# CC1350F128 register map
File version: 1.0
CPU: CM3 1.0, other endian, MPU, FPU, 3 interrupt priority bits
Registers are 32-bit, read-write, reset 0x0 unless marked. A register's access mark holds for its fields unless they carry their own. Offsets are from the block's base; [hi:lo] are bit positions.

## AUX_WUC — AUX Wake-up controller
Base 0x400C6000
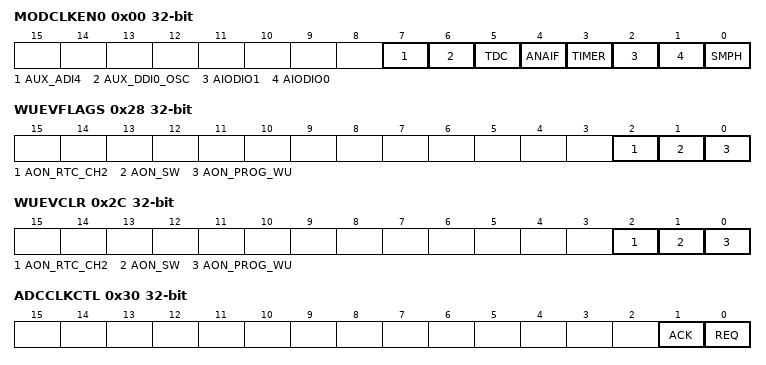
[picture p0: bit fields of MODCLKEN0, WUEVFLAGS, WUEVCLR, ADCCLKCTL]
0x00 MODCLKEN0 — Module Clock Enable Clock enable for each module in the AUX domain For use by the system CPU The settings in this register are OR'ed with the corresponding settings in MODCLKEN1. This allows the system CPU and AUX_SCE to request clocks independently. Settings take effect immediately.
  [7] AUX_ADI4 — [7:7] Enables (1) or disables (0) clock for AUX_ADI4.
    1=EN (System CPU has requested clock for AUX_ADI4); 0=DIS (System CPU has not requested clock for AUX_ADI4)
  [6] AUX_DDI0_OSC — [6:6] Enables (1) or disables (0) clock for AUX_DDI0_OSC.
    1=EN (System CPU has requested clock for AUX_DDI0_OSC); 0=DIS (System CPU has not requested clock for AUX_DDI0_OSC)
  [5] TDC — [5:5] Enables (1) or disables (0) clock for AUX_TDCIF. Note that the TDC counter and reference clock sources must be requested separately using TDCCLKCTL and REFCLKCTL, respectively.
    1=EN (System CPU has requested clock for TDC); 0=DIS (System CPU has not requested clock for TDC)
  [4] ANAIF — [4:4] Enables (1) or disables (0) clock for AUX_ANAIF. Note that the ADC internal clock must be requested separately using ADCCLKCTL.
    1=EN (System CPU has requested clock for ANAIF); 0=DIS (System CPU has not requested clock for ANAIF)
  [3] TIMER — [3:3] Enables (1) or disables (0) clock for AUX_TIMER.
    1=EN (System CPU has requested clock for TIMER); 0=DIS (System CPU has not requested clock for TIMER)
  [2] AIODIO1 — [2:2] Enables (1) or disables (0) clock for AUX_AIODIO1.
    1=EN (System CPU has requested clock for AIODIO1); 0=DIS (System CPU has not requested clock for AIODIO1)
  [1] AIODIO0 — [1:1] Enables (1) or disables (0) clock for AUX_AIODIO0.
    1=EN (System CPU has requested clock for AIODIO0); 0=DIS (System CPU has not requested clock for AIODIO0)
  [0] SMPH — [0:0] Enables (1) or disables (0) clock for AUX_SMPH.
    1=EN (System CPU has requested clock for SMPH); 0=DIS (System CPU has not requested clock for SMPH)
0x04 PWROFFREQ — Power Off Request Requests power off request for the AUX domain. When powered off, the power supply and clock is disabled. This may only be used when taking the entire device into shutdown mode (i.e. with full device reset when resuming operation). Power off is prevented if AON_WUC:AUXCTL.AUX_FORCE_ON has been set, or if MCUBUSCTL.DISCONNECT_REQ has been cleared.
  [0] REQ — [0:0] Power off request 0: No action 1: Request to power down AUX. Once set, this bit shall not be cleared. The bit will be reset again when AUX is powered up again. The request will only happen if AONCTLSTAT.AUX_FORCE_ON = 0 and MCUBUSSTAT.DISCONNECTED=1.
0x08 PWRDWNREQ — Power Down Request Request from AUX for system to enter power down. When system is in power down there is limited current supply available and the clock source is set by AON_WUC:AUXCLK.PWR_DWN_SRC
  [0] REQ — [0:0] Power down request 0: Request for system to be in active mode 1: Request for system to be in power down mode When REQ is 1 one shall assume that the system is in power down, and that current supply is limited. When setting REQ = 0, one shall assume that the system is in power down until PWRDWNACK.ACK = 0
0x0C PWRDWNACK — Power Down Acknowledgment
  [0] ACK ro — [0:0] Power down acknowledgment. Indicates whether the power down request given by PWRDWNREQ.REQ is captured by the AON domain or not 0: AUX can assume that the system is in active mode 1: The request for power down is acknowledged and the AUX must act like the system is in power down mode and power supply is limited The system CPU cannot use this bit since the bus bridge between MCU domain and AUX domain is always disconnected when this bit is set. For AUX_SCE use only
0x10 CLKLFREQ — Low Frequency Clock Request
  [0] REQ — [0:0] Low frequency request 0: Request clock frequency to be controlled by AON_WUC:AUXCLK and the system state 1: Request low frequency clock SCLK_LF as the clock source for AUX This bit must not be modified unless CLKLFACK.ACK matches the current value
0x14 CLKLFACK — Low Frequency Clock Acknowledgment
  [0] ACK ro — [0:0] Acknowledgment of CLKLFREQ.REQ 0: Acknowledgement that clock frequency is controlled by AON_WUC:AUXCLK and the system state 1: Acknowledgement that the low frequency clock SCLK_LF is the clock source for AUX
0x28 WUEVFLAGS — Wake-up Event Flags Status of wake-up events from the AON domain The event flags are cleared by setting the corresponding bits in WUEVCLR
  [2] AON_RTC_CH2 ro — [2:2] Indicates pending event from AON_RTC_CH2 compare. Note that this flag will be set whenever the AON_RTC_CH2 event happens, but that does not mean that this event is a wake-up event. To make the AON_RTC_CH2 a wake-up event for the AUX domain configure it as a wake-up event in AON_EVENT:AUXWUSEL.WU0_EV, AON_EVENT:AUXWUSEL.WU1_EV or AON_EVENT:AUXWUSEL.WU2_EV.
  [1] AON_SW ro — [1:1] Indicates pending event triggered by system CPU writing a 1 to AON_WUC:AUXCTL.SWEV.
  [0] AON_PROG_WU ro — [0:0] Indicates pending event triggered by the sources selected in AON_EVENT:AUXWUSEL.WU0_EV, AON_EVENT:AUXWUSEL.WU1_EV and AON_EVENT:AUXWUSEL.WU2_EV.
0x2C WUEVCLR — Wake-up Event Clear Clears wake-up events from the AON domain
  [2] AON_RTC_CH2 — [2:2] Set to clear the WUEVFLAGS.AON_RTC_CH2 wake-up event. Note that if RTC channel 2 is also set as source for AON_PROG_WU this field can also clear WUEVFLAGS.AON_PROG_WU This bit must remain set until WUEVFLAGS.AON_RTC_CH2 returns to 0.
  [1] AON_SW — [1:1] Set to clear the WUEVFLAGS.AON_SW wake-up event. This bit must remain set until WUEVFLAGS.AON_SW returns to 0.
  [0] AON_PROG_WU — [0:0] Set to clear the WUEVFLAGS.AON_PROG_WU wake-up event. Note only if an IO event is selected as wake-up event, is it possible to use this field to clear the source. Other sources cannot be cleared using this field. The IO pin needs to be assigned to AUX in the IOC and the input enable for the pin needs to be set in AIODIO0 or AIODIO1 for this clearing to take effect. This bit must remain set until WUEVFLAGS.AON_PROG_WU returns to 0.
0x30 ADCCLKCTL — ADC Clock Control Controls the ADC internal clock Note that the ADC command and data interface requires MODCLKEN0.ANAIF or MODCLKEN1.ANAIF also to be set
  [1] ACK ro — [1:1] Acknowledges the last value written to REQ.
  [0] REQ — [0:0] Enables(1) or disables (0) the ADC internal clock. This bit must not be modified unless ACK matches the current value.
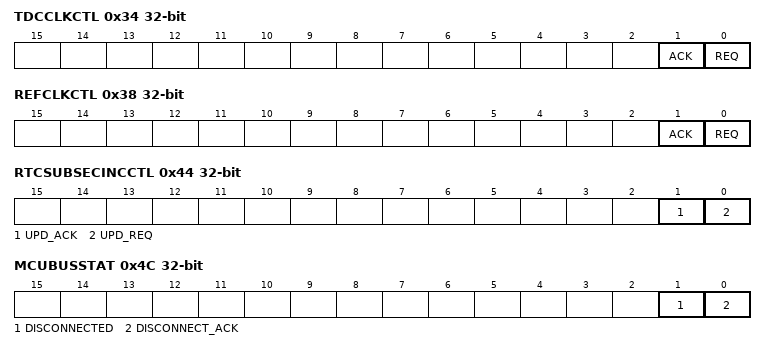
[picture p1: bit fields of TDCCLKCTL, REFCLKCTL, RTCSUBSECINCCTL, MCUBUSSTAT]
0x34 TDCCLKCTL — TDC Clock Control Controls the TDC counter clock source, which steps the TDC counter value The source of this clock is controlled by OSC_DIG:CTL0.ACLK_TDC_SRC_SEL.
  [1] ACK ro — [1:1] Acknowledges the last value written to REQ.
  [0] REQ — [0:0] Enables(1) or disables (0) the TDC counter clock source. This bit must not be modified unless ACK matches the current value.
0x38 REFCLKCTL — Reference Clock Control Controls the TDC reference clock source, which is to be compared against the TDC counter clock. The source of this clock is controlled by OSC_DIG:CTL0.ACLK_REF_SRC_SEL.
  [1] ACK ro — [1:1] Acknowledges the last value written to REQ.
  [0] REQ — [0:0] Enables(1) or disables (0) the TDC reference clock source. This bit must not be modified unless ACK matches the current value.
0x3C RTCSUBSECINC0 — Real Time Counter Sub Second Increment 0 New value for the real-time counter (AON_RTC) sub-second increment value, part corresponding to AON_RTC:SUBSECINC bits 15:0. After setting INC15_0 and RTCSUBSECINC1.INC23_16, the value is loaded into AON_RTC:SUBSECINC.VALUEINC by setting RTCSUBSECINCCTL.UPD_REQ.
  [15:0] INC15_0 — [15:0] Bits 15:0 of the RTC sub-second increment value.
0x40 RTCSUBSECINC1 — Real Time Counter Sub Second Increment 1 New value for the real-time counter (AON_RTC) sub-second increment value, part corresponding to AON_RTC:SUBSECINC bits 23:16. After setting RTCSUBSECINC0.INC15_0 and INC23_16, the value is loaded into AON_RTC:SUBSECINC.VALUEINC by setting RTCSUBSECINCCTL.UPD_REQ.
  [7:0] INC23_16 — [7:0] Bits 23:16 of the RTC sub-second increment value.
0x44 RTCSUBSECINCCTL — Real Time Counter Sub Second Increment Control
  [1] UPD_ACK ro — [1:1] Acknowledgment of the UPD_REQ.
  [0] UPD_REQ — [0:0] Signal that a new real time counter sub second increment value is available 0: New sub second increment is not available 1: New sub second increment is available This bit must not be modified unless UPD_ACK matches the current value.
0x48 MCUBUSCTL — MCU Bus Control Controls the connection between the AUX domain bus and the MCU domain bus. The buses must be disconnected to allow power-down or power-off of the AUX domain.
  [0] DISCONNECT_REQ — [0:0] Requests the AUX domain bus to be disconnected from the MCU domain bus. The request has no effect when AON_WUC:AUX_CTL.AUX_FORCE_ON is set. The disconnection status can be monitored through MCUBUSSTAT. Note however that this register cannot be read by the system CPU while disconnected. It is recommended that this bit is set and remains set after initial power-up, and that the system CPU uses AON_WUC:AUX_CTL.AUX_FORCE_ON to connect/disconnect the bus.
0x4C MCUBUSSTAT — MCU Bus Status Indicates the connection state of the AUX domain and MCU domain buses. Note that this register cannot be read from the MCU domain while disconnected, and is therefore only useful for the AUX_SCE.
  [1] DISCONNECTED ro — [1:1] Indicates whether the AUX domain and MCU domain buses are currently disconnected (1) or connected (0).
  [0] DISCONNECT_ACK ro — [0:0] Acknowledges reception of the bus disconnection request, by matching the value of MCUBUSCTL.DISCONNECT_REQ. Note that if AON_WUC:AUXCTL.AUX_FORCE_ON = 1 a reconnect to the MCU domain bus will be made regardless of the state of MCUBUSCTL.DISCONNECT_REQ
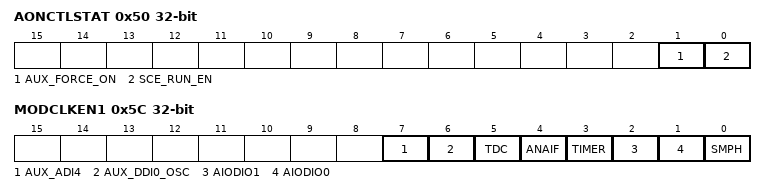
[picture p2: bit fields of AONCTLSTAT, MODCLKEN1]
0x50 AONCTLSTAT — AON Domain Control Status Status of AUX domain control from AON_WUC.
  [1] AUX_FORCE_ON ro — [1:1] Status of AON_WUC:AUX_CTL.AUX_FORCE_ON.
  [0] SCE_RUN_EN ro — [0:0] Status of AON_WUC:AUX_CTL.SCE_RUN_EN.
0x54 AUXIOLATCH — AUX Input Output Latch Controls latching of signals between AUX_AIODIO0/AUX_AIODIO1 and AON_IOC.
  [0] EN — [0:0] Opens (1) or closes (0) the AUX_AIODIO0/AUX_AIODIO1 signal latching. At startup, set EN = TRANSP before configuring AUX_AIODIO0/AUX_AIODIO1 and subsequently selecting AUX mode in the AON_IOC. When powering off the AUX domain (using PWROFFREQ.REQ), set EN = STATIC in advance preserve the current state (mode and output value) of the I/O pins.
    1=TRANSP (Latches are transparent ( open )); 0=STATIC (Latches are static ( closed ))
0x5C MODCLKEN1 — Module Clock Enable 1 Clock enable for each module in the AUX domain, for use by the AUX_SCE. Settings take effect immediately. The settings in this register are OR'ed with the corresponding settings in MODCLKEN0. This allows system CPU and AUX_SCE to request clocks independently.
  [7] AUX_ADI4 — [7:7] Enables (1) or disables (0) clock for AUX_ADI4.
    1=EN (AUX_SCE has requested clock for AUX_ADI4); 0=DIS (AUX_SCE has not requested clock for AUX_ADI4)
  [6] AUX_DDI0_OSC — [6:6] Enables (1) or disables (0) clock for AUX_DDI0_OSC.
    1=EN (AUX_SCE has requested clock for AUX_DDI0_OSC); 0=DIS (AUX_SCE has not requested clock for AUX_DDI0_OSC)
  [5] TDC — [5:5] Software should not rely on the value of a reserved. Writing any other value than the reset value may result in undefined behavior.
  [4] ANAIF — [4:4] Enables (1) or disables (0) clock for AUX_ANAIF.
    1=EN (AUX_SCE has requested clock for ANAIF); 0=DIS (AUX_SCE has not requested clock for ANAIF)
  [3] TIMER — [3:3] Enables (1) or disables (0) clock for AUX_TIMER.
    1=EN (AUX_SCE has requested clock for TIMER); 0=DIS (AUX_SCE has not requested clock for TIMER)
  [2] AIODIO1 — [2:2] Enables (1) or disables (0) clock for AUX_AIODIO1.
    1=EN (AUX_SCE has requested clock for AIODIO1); 0=DIS (AUX_SCE has not requested clock for AIODIO1)
  [1] AIODIO0 — [1:1] Enables (1) or disables (0) clock for AUX_AIODIO0.
    1=EN (AUX_SCE has requested clock for AIODIO0); 0=DIS (AUX_SCE has not requested clock for AIODIO0)
  [0] SMPH — [0:0] Enables (1) or disables (0) clock for AUX_SMPH.
    1=EN (AUX_SCE has requested clock for SMPH); 0=DIS (AUX_SCE has not requested clock for SMPH)
